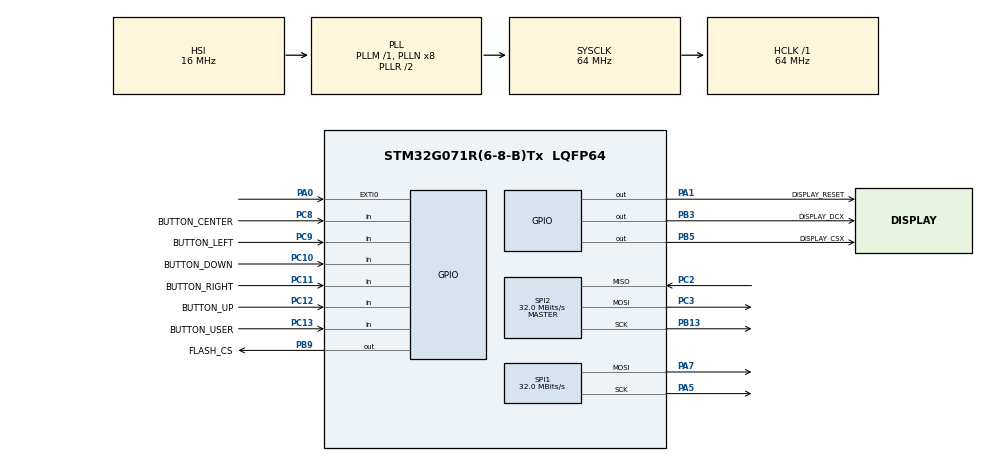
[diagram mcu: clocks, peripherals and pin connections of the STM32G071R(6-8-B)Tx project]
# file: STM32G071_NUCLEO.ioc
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CRC.DefaultInitValueUse=DEFAULT_INIT_VALUE_ENABLE
CRC.DefaultPolynomialUse=DEFAULT_POLYNOMIAL_ENABLE
CRC.InputDataFormat=CRC_INPUTDATA_FORMAT_BYTES
CRC.InputDataInversionMode=CRC_INPUTDATA_INVERSION_NONE
CRC.OutputDataInversionMode=CRC_OUTPUTDATA_INVERSION_DISABLE
Dma.Request0=SPI1_TX
Dma.Request1=SPI2_RX
Dma.Request2=SPI2_TX
Dma.SPI1_TX.0.Direction=DMA_MEMORY_TO_PERIPH
Dma.SPI1_TX.0.EventEnable=DISABLE
Dma.SPI1_TX.0.Instance=DMA1_Channel1
Dma.SPI1_TX.0.MemDataAlignment=DMA_MDATAALIGN_HALFWORD
Dma.SPI1_TX.0.MemInc=DMA_MINC_ENABLE
Dma.SPI1_TX.0.Mode=DMA_NORMAL
Dma.SPI1_TX.0.PeriphDataAlignment=DMA_PDATAALIGN_HALFWORD
Dma.SPI1_TX.0.PeriphInc=DMA_PINC_DISABLE
Dma.SPI1_TX.0.Polarity=HAL_DMAMUX_REQ_GEN_RISING
Dma.SPI1_TX.0.Priority=DMA_PRIORITY_LOW
Dma.SPI1_TX.0.RequestNumber=1
Dma.SPI1_TX.0.SignalID=NONE
Dma.SPI1_TX.0.SyncEnable=DISABLE
Dma.SPI1_TX.0.SyncPolarity=HAL_DMAMUX_SYNC_NO_EVENT
Dma.SPI1_TX.0.SyncRequestNumber=1
Dma.SPI1_TX.0.SyncSignalID=NONE
Dma.SPI2_RX.1.Direction=DMA_PERIPH_TO_MEMORY
Dma.SPI2_RX.1.EventEnable=DISABLE
Dma.SPI2_RX.1.Instance=DMA1_Channel2
Dma.SPI2_RX.1.MemDataAlignment=DMA_MDATAALIGN_BYTE
Dma.SPI2_RX.1.MemInc=DMA_MINC_ENABLE
Dma.SPI2_RX.1.Mode=DMA_NORMAL
Dma.SPI2_RX.1.PeriphDataAlignment=DMA_PDATAALIGN_BYTE
Dma.SPI2_RX.1.PeriphInc=DMA_PINC_DISABLE
Dma.SPI2_RX.1.Polarity=HAL_DMAMUX_REQ_GEN_RISING
Dma.SPI2_RX.1.Priority=DMA_PRIORITY_LOW
Dma.SPI2_RX.1.RequestNumber=1
Dma.SPI2_RX.1.SignalID=NONE
Dma.SPI2_RX.1.SyncEnable=DISABLE
Dma.SPI2_RX.1.SyncPolarity=HAL_DMAMUX_SYNC_NO_EVENT
Dma.SPI2_RX.1.SyncRequestNumber=1
Dma.SPI2_RX.1.SyncSignalID=NONE
Dma.SPI2_TX.2.Direction=DMA_MEMORY_TO_PERIPH
Dma.SPI2_TX.2.EventEnable=DISABLE
Dma.SPI2_TX.2.Instance=DMA1_Channel3
Dma.SPI2_TX.2.MemDataAlignment=DMA_MDATAALIGN_BYTE
Dma.SPI2_TX.2.MemInc=DMA_MINC_ENABLE
Dma.SPI2_TX.2.Mode=DMA_NORMAL
Dma.SPI2_TX.2.PeriphDataAlignment=DMA_PDATAALIGN_BYTE
Dma.SPI2_TX.2.PeriphInc=DMA_PINC_DISABLE
Dma.SPI2_TX.2.Polarity=HAL_DMAMUX_REQ_GEN_RISING
Dma.SPI2_TX.2.Priority=DMA_PRIORITY_LOW
Dma.SPI2_TX.2.RequestNumber=1
Dma.SPI2_TX.2.SignalID=NONE
Dma.SPI2_TX.2.SyncEnable=DISABLE
Dma.SPI2_TX.2.SyncPolarity=HAL_DMAMUX_SYNC_NO_EVENT
Dma.SPI2_TX.2.SyncRequestNumber=1
Dma.SPI2_TX.2.SyncSignalID=NONE
Mcu.Family=STM32G0
Mcu.Name=STM32G071R(6-8-B)Tx
Mcu.Package=LQFP64
NVIC.DMA1_Channel1_IRQn=true\:0\:0\:false\:false\:true\:false\:false
NVIC.DMA1_Channel2_3_IRQn=true\:0\:0\:false\:false\:true\:false\:false
NVIC.EXTI0_1_IRQn=true\:0\:0\:false\:false\:true\:true\:true
NVIC.SPI1_IRQn=true\:0\:0\:false\:false\:true\:true\:true
NVIC.SPI2_IRQn=true\:0\:0\:false\:false\:true\:true\:true
NVIC.TIM6_DAC_LPTIM1_IRQn=true\:0\:0\:false\:false\:true\:true\:true
PA0.GPIO_ModeDefaultEXTI=GPIO_MODE_IT_RISING_FALLING
PA0.Signal=GPXTI0
PA1.GPIO_Label=DISPLAY_RESET
PA1.GPIO_PuPd=GPIO_PULLUP
PA1.GPIO_Speed=GPIO_SPEED_FREQ_HIGH
PA1.Signal=GPIO_Output
PA13.Mode=Serial_Wire
PA13.Signal=SYS_SWDIO
PA14-BOOT0.Mode=Serial_Wire
PA14-BOOT0.Signal=SYS_SWCLK
PA5.GPIO_PuPd=GPIO_PULLDOWN
PA5.GPIO_Speed=GPIO_SPEED_FREQ_HIGH
PA5.Mode=TX_Only_Simplex_Unidirect_Master
PA5.Signal=SPI1_SCK
PA7.GPIO_PuPd=GPIO_PULLDOWN
PA7.GPIO_Speed=GPIO_SPEED_FREQ_HIGH
PA7.Mode=TX_Only_Simplex_Unidirect_Master
PA7.Signal=SPI1_MOSI
PB13.GPIO_PuPd=GPIO_PULLDOWN
PB13.GPIO_Speed=GPIO_SPEED_FREQ_HIGH
PB13.Mode=Full_Duplex_Master
PB13.Signal=SPI2_SCK
PB3.GPIO_Label=DISPLAY_DCX
PB3.GPIO_PuPd=GPIO_PULLUP
PB3.GPIO_Speed=GPIO_SPEED_FREQ_VERY_HIGH
PB3.PinState=GPIO_PIN_SET
PB3.Signal=GPIO_Output
PB5.GPIO_Label=DISPLAY_CSX
PB5.GPIO_PuPd=GPIO_PULLUP
PB5.GPIO_Speed=GPIO_SPEED_FREQ_VERY_HIGH
PB5.PinState=GPIO_PIN_SET
PB5.Signal=GPIO_Output
PB9.GPIO_FM9=SYSCFG_FASTMODEPLUS_PB9
PB9.GPIO_Label=FLASH_CS
PB9.GPIO_Speed=GPIO_SPEED_FREQ_VERY_HIGH
PB9.PinState=GPIO_PIN_SET
PB9.Signal=GPIO_Output
PC10.GPIO_Label=BUTTON_DOWN
PC10.GPIO_PuPd=GPIO_PULLUP
PC10.Signal=GPIO_Input
PC11.GPIO_Label=BUTTON_RIGHT
PC11.GPIO_PuPd=GPIO_PULLUP
PC11.Signal=GPIO_Input
PC12.GPIO_Label=BUTTON_UP
PC12.GPIO_PuPd=GPIO_PULLUP
PC12.Signal=GPIO_Input
PC13.GPIO_Label=BUTTON_USER
PC13.GPIO_PuPd=GPIO_PULLUP
PC13.Signal=GPIO_Input
PC14-OSC32_IN\ (PC14).Mode=LSE-External-Oscillator
PC14-OSC32_IN\ (PC14).Signal=RCC_OSC32_IN
PC15-OSC32_OUT\ (PC15).Mode=LSE-External-Oscillator
PC15-OSC32_OUT\ (PC15).Signal=RCC_OSC32_OUT
PC2.GPIO_PuPd=GPIO_PULLDOWN
PC2.GPIO_Speed=GPIO_SPEED_FREQ_HIGH
PC2.Mode=Full_Duplex_Master
PC2.Signal=SPI2_MISO
PC3.GPIO_PuPd=GPIO_PULLDOWN
PC3.GPIO_Speed=GPIO_SPEED_FREQ_HIGH
PC3.Mode=Full_Duplex_Master
PC3.Signal=SPI2_MOSI
PC8.GPIO_Label=BUTTON_CENTER
PC8.GPIO_PuPd=GPIO_PULLUP
PC8.Signal=GPIO_Input
PC9.GPIO_Label=BUTTON_LEFT
PC9.GPIO_PuPd=GPIO_PULLUP
PC9.Signal=GPIO_Input
PF0-OSC_IN\ (PF0).Mode=HSE-External-Clock-Source
PF0-OSC_IN\ (PF0).Signal=RCC_OSC_IN
ProjectManager.HeapSize=0x200
ProjectManager.StackSize=0x800
ProjectManager.TargetToolchain=STM32CubeIDE
RCC.ADCFreq_Value=64000000
RCC.AHBFreq_Value=64000000
RCC.CortexFreq_Value=64000000
RCC.EXTERNAL_CLOCK_VALUE=48000
RCC.FLatency=FLASH_LATENCY_2
RCC.HCLKFreq_Value=64000000
RCC.HSE_VALUE=8000000
RCC.HSI_VALUE=16000000
RCC.SYSCLKFreq_VALUE=64000000
RCC.SYSCLKSource=RCC_SYSCLKSOURCE_PLLCLK
RCC.VCOOutputFreq_Value=128000000
SPI1.BaudRatePrescaler=SPI_BAUDRATEPRESCALER_2
SPI1.CLKPhase=SPI_PHASE_1EDGE
SPI1.CLKPolarity=SPI_POLARITY_LOW
SPI1.CRCCalculation=SPI_CRCCALCULATION_DISABLE
SPI1.CalculateBaudRate=32.0 MBits/s
SPI1.DataSize=SPI_DATASIZE_8BIT
SPI1.Direction=SPI_DIRECTION_2LINES
SPI1.FirstBit=SPI_FIRSTBIT_MSB
SPI1.Mode=SPI_MODE_MASTER
SPI1.NSS=SPI_NSS_SOFT
SPI1.NSSPMode=SPI_NSS_PULSE_DISABLE
SPI1.TIMode=SPI_TIMODE_DISABLE
SPI1.VirtualType=VM_MASTER
SPI2.BaudRatePrescaler=SPI_BAUDRATEPRESCALER_2
SPI2.CLKPhase=SPI_PHASE_1EDGE
SPI2.CLKPolarity=SPI_POLARITY_LOW
SPI2.CalculateBaudRate=32.0 MBits/s
SPI2.DataSize=SPI_DATASIZE_8BIT
SPI2.Direction=SPI_DIRECTION_2LINES
SPI2.Mode=SPI_MODE_MASTER
SPI2.NSSPMode=SPI_NSS_PULSE_DISABLE
SPI2.VirtualType=VM_MASTER
STMicroelectronics.X-CUBE-TOUCHGFX.4.18.0.ApplicationCcGraphicsJjApplication=TouchGFXOoGenerator
STMicroelectronics.X-CUBE-TOUCHGFX.4.18.0.tgfx_buffering_strategy=Partial
STMicroelectronics.X-CUBE-TOUCHGFX.4.18.0.tgfx_custom_height=320
STMicroelectronics.X-CUBE-TOUCHGFX.4.18.0.tgfx_custom_width=240
STMicroelectronics.X-CUBE-TOUCHGFX.4.18.0.tgfx_datareader=Enabled
STMicroelectronics.X-CUBE-TOUCHGFX.4.18.0.tgfx_partial_fb_stay_behind_beam=Enabled
STMicroelectronics.X-CUBE-TOUCHGFX.4.18.0.tgfx_partialfb_transmit_strategy=Enabled
STMicroelectronics.X-CUBE-TOUCHGFX.4.18.0.tgfx_serial_flash=Enabled
TIM6.AutoReloadPreload=TIM_AUTORELOAD_PRELOAD_DISABLE
TIM6.Period=0xFFFF
TIM6.Prescaler=2520
TIM6.TIM_MasterOutputTrigger=TIM_TRGO_ENABLE
VP_CRC_VS_CRC.Mode=CRC_Activate
VP_STMicroelectronics.X-CUBE-TOUCHGFX_VS_GraphicsJjApplication_4.18.0.Mode=GraphicsJjApplication
VP_SYS_VS_DBSignals.Mode=DisableDeadBatterySignals
VP_TIM6_VS_ClockSourceINT.Mode=Enable_Timer
board=NUCLEO-G071RB

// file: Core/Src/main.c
/* USER CODE BEGIN Header */
/**
  ******************************************************************************
  * @file           : main.c
  * @brief          : Main program body
  ******************************************************************************
  * @attention
  *
  * <h2><center>&copy; Copyright (c) 2020 STMicroelectronics.
  * All rights reserved.</center></h2>
  *
  * This software component is licensed by ST under BSD 3-Clause license,
  * the "License"; You may not use this file except in compliance with the
  * License. You may obtain a copy of the License at:
  *                        opensource.org/licenses/BSD-3-Clause
  *
  ******************************************************************************
  */
/* USER CODE END Header */
#include "main.h"
#include "app_touchgfx.h"

CRC_HandleTypeDef hcrc;

SPI_HandleTypeDef hspi1;
SPI_HandleTypeDef hspi2;
DMA_HandleTypeDef hdma_spi1_tx;
DMA_HandleTypeDef hdma_spi2_rx;
DMA_HandleTypeDef hdma_spi2_tx;

TIM_HandleTypeDef htim6;

void SystemClock_Config(void);
static void MX_GPIO_Init(void);
static void MX_DMA_Init(void);
static void MX_SPI1_Init(void);
static void MX_CRC_Init(void);
static void MX_SPI2_Init(void);
static void MX_TIM6_Init(void);

int main(void)
{

  /* MCU Configuration--------------------------------------------------------*/

  /* Reset of all peripherals, Initializes the Flash interface and the Systick. */
  HAL_Init();

  /* Configure the system clock */
  SystemClock_Config();

  /* Initialize all configured peripherals */
  MX_GPIO_Init();
  MX_DMA_Init();
  MX_SPI1_Init();
  MX_CRC_Init();
  MX_SPI2_Init();
  MX_TIM6_Init();
  MX_TouchGFX_Init();

  /* Infinite loop */
  while (1)
  {

  MX_TouchGFX_Process();
  }
}

void SystemClock_Config(void)
{
  RCC_OscInitTypeDef RCC_OscInitStruct = {0};
  RCC_ClkInitTypeDef RCC_ClkInitStruct = {0};

  /** Configure the main internal regulator output voltage
  */
  HAL_PWREx_ControlVoltageScaling(PWR_REGULATOR_VOLTAGE_SCALE1);
  /** Initializes the RCC Oscillators according to the specified parameters
  * in the RCC_OscInitTypeDef structure.
  */
  RCC_OscInitStruct.OscillatorType = RCC_OSCILLATORTYPE_HSI;
  RCC_OscInitStruct.HSIState = RCC_HSI_ON;
  RCC_OscInitStruct.HSIDiv = RCC_HSI_DIV1;
  RCC_OscInitStruct.HSICalibrationValue = RCC_HSICALIBRATION_DEFAULT;
  RCC_OscInitStruct.PLL.PLLState = RCC_PLL_ON;
  RCC_OscInitStruct.PLL.PLLSource = RCC_PLLSOURCE_HSI;
  RCC_OscInitStruct.PLL.PLLM = RCC_PLLM_DIV1;
  RCC_OscInitStruct.PLL.PLLN = 8;
  RCC_OscInitStruct.PLL.PLLP = RCC_PLLP_DIV2;
  RCC_OscInitStruct.PLL.PLLQ = RCC_PLLQ_DIV2;
  RCC_OscInitStruct.PLL.PLLR = RCC_PLLR_DIV2;
  if (HAL_RCC_OscConfig(&RCC_OscInitStruct) != HAL_OK)
  {
    Error_Handler();
  }
  /** Initializes the CPU, AHB and APB buses clocks
  */
  RCC_ClkInitStruct.ClockType = RCC_CLOCKTYPE_HCLK|RCC_CLOCKTYPE_SYSCLK
                              |RCC_CLOCKTYPE_PCLK1;
  RCC_ClkInitStruct.SYSCLKSource = RCC_SYSCLKSOURCE_PLLCLK;
  RCC_ClkInitStruct.AHBCLKDivider = RCC_SYSCLK_DIV1;
  RCC_ClkInitStruct.APB1CLKDivider = RCC_HCLK_DIV1;

  if (HAL_RCC_ClockConfig(&RCC_ClkInitStruct, FLASH_LATENCY_2) != HAL_OK)
  {
    Error_Handler();
  }
}

static void MX_CRC_Init(void)
{

  hcrc.Instance = CRC;
  hcrc.Init.DefaultPolynomialUse = DEFAULT_POLYNOMIAL_ENABLE;
  hcrc.Init.DefaultInitValueUse = DEFAULT_INIT_VALUE_ENABLE;
  hcrc.Init.InputDataInversionMode = CRC_INPUTDATA_INVERSION_NONE;
  hcrc.Init.OutputDataInversionMode = CRC_OUTPUTDATA_INVERSION_DISABLE;
  hcrc.InputDataFormat = CRC_INPUTDATA_FORMAT_BYTES;
  if (HAL_CRC_Init(&hcrc) != HAL_OK)
  {
    Error_Handler();
  }

}

static void MX_SPI1_Init(void)
{

  /* SPI1 parameter configuration*/
  hspi1.Instance = SPI1;
  hspi1.Init.Mode = SPI_MODE_MASTER;
  hspi1.Init.Direction = SPI_DIRECTION_2LINES;
  hspi1.Init.DataSize = SPI_DATASIZE_8BIT;
  hspi1.Init.CLKPolarity = SPI_POLARITY_LOW;
  hspi1.Init.CLKPhase = SPI_PHASE_1EDGE;
  hspi1.Init.NSS = SPI_NSS_SOFT;
  hspi1.Init.BaudRatePrescaler = SPI_BAUDRATEPRESCALER_2;
  hspi1.Init.FirstBit = SPI_FIRSTBIT_MSB;
  hspi1.Init.TIMode = SPI_TIMODE_DISABLE;
  hspi1.Init.CRCCalculation = SPI_CRCCALCULATION_DISABLE;
  hspi1.Init.CRCPolynomial = 7;
  hspi1.Init.CRCLength = SPI_CRC_LENGTH_DATASIZE;
  hspi1.Init.NSSPMode = SPI_NSS_PULSE_DISABLE;
  if (HAL_SPI_Init(&hspi1) != HAL_OK)
  {
    Error_Handler();
  }

}

static void MX_SPI2_Init(void)
{

  /* SPI2 parameter configuration*/
  hspi2.Instance = SPI2;
  hspi2.Init.Mode = SPI_MODE_MASTER;
  hspi2.Init.Direction = SPI_DIRECTION_2LINES;
  hspi2.Init.DataSize = SPI_DATASIZE_8BIT;
  hspi2.Init.CLKPolarity = SPI_POLARITY_LOW;
  hspi2.Init.CLKPhase = SPI_PHASE_1EDGE;
  hspi2.Init.NSS = SPI_NSS_SOFT;
  hspi2.Init.BaudRatePrescaler = SPI_BAUDRATEPRESCALER_2;
  hspi2.Init.FirstBit = SPI_FIRSTBIT_MSB;
  hspi2.Init.TIMode = SPI_TIMODE_DISABLE;
  hspi2.Init.CRCCalculation = SPI_CRCCALCULATION_DISABLE;
  hspi2.Init.CRCPolynomial = 7;
  hspi2.Init.CRCLength = SPI_CRC_LENGTH_DATASIZE;
  hspi2.Init.NSSPMode = SPI_NSS_PULSE_DISABLE;
  if (HAL_SPI_Init(&hspi2) != HAL_OK)
  {
    Error_Handler();
  }

}

static void MX_TIM6_Init(void)
{

  TIM_MasterConfigTypeDef sMasterConfig = {0};

  htim6.Instance = TIM6;
  htim6.Init.Prescaler = 2520;
  htim6.Init.CounterMode = TIM_COUNTERMODE_UP;
  htim6.Init.Period = 0xFFFF;
  htim6.Init.AutoReloadPreload = TIM_AUTORELOAD_PRELOAD_DISABLE;
  if (HAL_TIM_Base_Init(&htim6) != HAL_OK)
  {
    Error_Handler();
  }
  sMasterConfig.MasterOutputTrigger = TIM_TRGO_ENABLE;
  sMasterConfig.MasterSlaveMode = TIM_MASTERSLAVEMODE_DISABLE;
  if (HAL_TIMEx_MasterConfigSynchronization(&htim6, &sMasterConfig) != HAL_OK)
  {
    Error_Handler();
  }
  /* USER CODE BEGIN TIM6_Init 2 */
  //HAL_TIM_Base_Init(&htim6);
  //HAL_TIM_Base_Start_IT(&htim6);
  /* USER CODE END TIM6_Init 2 */

}

static void MX_DMA_Init(void)
{

  /* DMA controller clock enable */
  __HAL_RCC_DMA1_CLK_ENABLE();

  /* DMA interrupt init */
  /* DMA1_Channel1_IRQn interrupt configuration */
  HAL_NVIC_SetPriority(DMA1_Channel1_IRQn, 0, 0);
  HAL_NVIC_EnableIRQ(DMA1_Channel1_IRQn);
  /* DMA1_Channel2_3_IRQn interrupt configuration */
  HAL_NVIC_SetPriority(DMA1_Channel2_3_IRQn, 0, 0);
  HAL_NVIC_EnableIRQ(DMA1_Channel2_3_IRQn);

}

static void MX_GPIO_Init(void)
{
  GPIO_InitTypeDef GPIO_InitStruct = {0};

  /* GPIO Ports Clock Enable */
  __HAL_RCC_GPIOC_CLK_ENABLE();
  __HAL_RCC_GPIOF_CLK_ENABLE();
  __HAL_RCC_GPIOA_CLK_ENABLE();
  __HAL_RCC_GPIOB_CLK_ENABLE();

  /*Configure GPIO pin Output Level */
  HAL_GPIO_WritePin(DISPLAY_RESET_GPIO_Port, DISPLAY_RESET_Pin, GPIO_PIN_RESET);

  /*Configure GPIO pin Output Level */
  HAL_GPIO_WritePin(GPIOB, DISPLAY_DCX_Pin|DISPLAY_CSX_Pin|FLASH_CS_Pin, GPIO_PIN_SET);

  /*Configure GPIO pins : BUTTON_RIGHT_Pin BUTTON_UP_Pin BUTTON_USER_Pin BUTTON_CENTER_Pin
                           BUTTON_LEFT_Pin BUTTON_DOWN_Pin */
  GPIO_InitStruct.Pin = BUTTON_RIGHT_Pin|BUTTON_UP_Pin|BUTTON_USER_Pin|BUTTON_CENTER_Pin
                          |BUTTON_LEFT_Pin|BUTTON_DOWN_Pin;
  GPIO_InitStruct.Mode = GPIO_MODE_INPUT;
  GPIO_InitStruct.Pull = GPIO_PULLUP;
  HAL_GPIO_Init(GPIOC, &GPIO_InitStruct);

  /*Configure GPIO pin : PA0 */
  GPIO_InitStruct.Pin = GPIO_PIN_0;
  GPIO_InitStruct.Mode = GPIO_MODE_IT_RISING_FALLING;
  GPIO_InitStruct.Pull = GPIO_NOPULL;
  HAL_GPIO_Init(GPIOA, &GPIO_InitStruct);

  /*Configure GPIO pin : DISPLAY_RESET_Pin */
  GPIO_InitStruct.Pin = DISPLAY_RESET_Pin;
  GPIO_InitStruct.Mode = GPIO_MODE_OUTPUT_PP;
  GPIO_InitStruct.Pull = GPIO_PULLUP;
  GPIO_InitStruct.Speed = GPIO_SPEED_FREQ_HIGH;
  HAL_GPIO_Init(DISPLAY_RESET_GPIO_Port, &GPIO_InitStruct);

  /*Configure GPIO pins : DISPLAY_DCX_Pin DISPLAY_CSX_Pin */
  GPIO_InitStruct.Pin = DISPLAY_DCX_Pin|DISPLAY_CSX_Pin;
  GPIO_InitStruct.Mode = GPIO_MODE_OUTPUT_PP;
  GPIO_InitStruct.Pull = GPIO_PULLUP;
  GPIO_InitStruct.Speed = GPIO_SPEED_FREQ_VERY_HIGH;
  HAL_GPIO_Init(GPIOB, &GPIO_InitStruct);

  /*Configure GPIO pin : FLASH_CS_Pin */
  GPIO_InitStruct.Pin = FLASH_CS_Pin;
  GPIO_InitStruct.Mode = GPIO_MODE_OUTPUT_PP;
  GPIO_InitStruct.Pull = GPIO_NOPULL;
  GPIO_InitStruct.Speed = GPIO_SPEED_FREQ_VERY_HIGH;
  HAL_GPIO_Init(FLASH_CS_GPIO_Port, &GPIO_InitStruct);

  /**/
  __HAL_SYSCFG_FASTMODEPLUS_ENABLE(SYSCFG_FASTMODEPLUS_PB9);

  /* EXTI interrupt init*/
  HAL_NVIC_SetPriority(EXTI0_1_IRQn, 0, 0);
  HAL_NVIC_EnableIRQ(EXTI0_1_IRQn);

}

void Error_Handler(void)
{
}

/************************ (C) COPYRIGHT STMicroelectronics *****END OF FILE****/
